# MB9AF1AxM register map
File version: 1.1
CPU: 
Registers are 8-bit, read-write, reset 0x0 unless marked. A register's access mark holds for its fields unless they carry their own. Offsets are from the block's base; [hi:lo] are bit positions; {n}, {i} and the like mark numbered series.

## MFT_PPG — PPG Configuration
Base 0x40024000
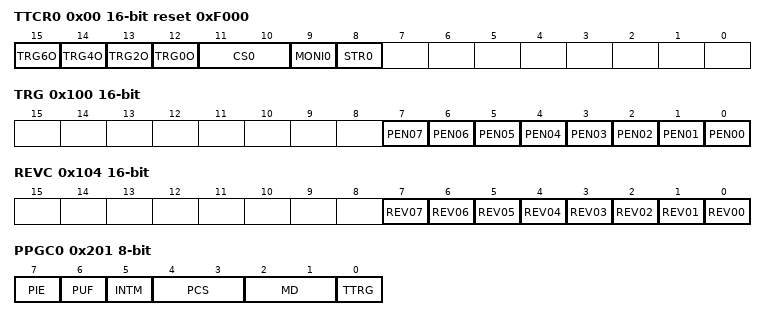
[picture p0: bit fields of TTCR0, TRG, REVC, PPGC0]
0x00 TTCR0 16-bit reset 0xF000 — PPG Start Trigger Control Register 0
  [15] TRG6O — PPG6 trigger stop bit
  [14] TRG4O — PPG4 trigger stop bit
  [13] TRG2O — PPG2 trigger stop bit
  [12] TRG0O — PPG0 trigger stop bit
  [11:10] CS0 — 8-bit UP counter clock select bits for comparison
  [9] MONI0 ro — 8-bit UP counter operation state monitor bit for comparison
  [8] STR0 — 8-bit UP counter operation enable bit for comparison
0x08 COMP0 16-bit (reset mask 0xFF00) — PPG Compare Register 0
0x0C COMP2 — PPG Compare Register 2
0x10 COMP4 32-bit reset not defined — PPG Compare Register 4
0x14 COMP6 32-bit reset not defined — PPG Compare Register 6
0x100 TRG 16-bit — PPG Start Register 0
  [n] PEN{n:02} (n=0..7) — PPG{n} Start Trigger bit
0x104 REVC 16-bit — Output Reverse Register 0
  [n] REV{n:02} (n=0..7) — PPG{n} Output Reverse Enable bit
0x200 PPGC1 32-bit reset not defined — PPG Operation Mode Control Register 1
0x201 PPGC0 — PPG Operation Mode Control Register 0
  [7] PIE — PPG Interrupt Enable bit
  [6] PUF — PPG Counter Underflow bit
  [5] INTM — Interrupt Mode Select bit
  [4:3] PCS — PPG DOWN Counter Operation Clock Select bits
  [2:1] MD — PPG Operation Mode Set bits
  [0] TTRG — PPG start trigger select bit
0x204 PPGC3 32-bit reset not defined — PPG Operation Mode Control Register 3
0x205 PPGC2 32-bit reset not defined — PPG Operation Mode Control Register 2
0x208 PRLL0 reset not defined — PPG0 Reload Registers Low
  [7:0] PRLL — Reload Registers Low
0x209 PRLH0 reset not defined — PPG0 Reload Registers High
  [7:0] PRLH — Reload Registers High
{0x208+4i} PRLL{i} 32-bit reset not defined (i=1..3) — PPG{i} Reload Registers Low
{0x209+4i} PRLH{i} 32-bit reset not defined (i=1..3) — PPG{i} Reload Registers High
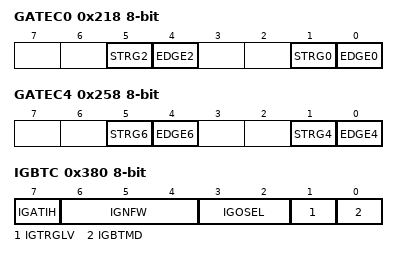
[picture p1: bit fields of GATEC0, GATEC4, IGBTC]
0x218 GATEC0 — PPG Gate Function Control Registers 0
  [5] STRG2 — Select a trigger for PPG2
  [4] EDGE2 — Select Start Effective Level for PPG2
  [1] STRG0 — Select a trigger for PPG0
  [0] EDGE0 — Select Start Effective Level for PPG0
0x240 PPGC5 32-bit reset not defined — PPG Operation Mode Control Register 5
0x241 PPGC4 32-bit reset not defined — PPG Operation Mode Control Register 4
0x244 PPGC7 32-bit reset not defined — PPG Operation Mode Control Register 7
0x245 PPGC6 32-bit reset not defined — PPG Operation Mode Control Register 6
{0x238+4i} PRLL{i} 32-bit reset not defined (i=4..7) — PPG{i} Reload Registers Low
{0x239+4i} PRLH{i} 32-bit reset not defined (i=4..7) — PPG{i} Reload Registers High
0x258 GATEC4 — PPG Gate Function Control Registers 4
  [5] STRG6 — Select a trigger for PPG6
  [4] EDGE6 — Select Start Effective Level for PPG6
  [1] STRG4 — Select a trigger for PPG4
  [0] EDGE4 — Select Start Effective Level for PPG4
0x380 IGBTC — IGBT Mode Control Register
  [7] IGATIH — Stop prohibition mode selection in output active bit
  [6:4] IGNFW — Noise filter width selection bit
  [3:2] IGOSEL — Output level selection bit
  [1] IGTRGLV — Trigger input level selection bit
  [0] IGBTMD — IGBT mode selection bit

## DAC — D/A Converter
Base 0x40028000
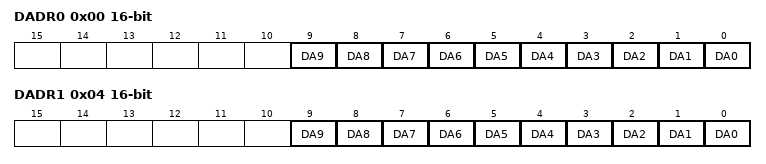
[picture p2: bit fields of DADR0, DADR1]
0x00 DADR0 16-bit reset not defined — D/A Data Register
  [n] DA{n} (n=0..9) — Bit{n} of DADR0
0x02 DACR0 reset not defined — D/A Control Register
  [0] DAE — D/A converter operation enable bit
0x04 DADR1 16-bit reset not defined — D/A Data Register
  [n] DA{n} (n=0..9) — Bit{n} of DADR1
0x06 DACR1 reset not defined — D/A Control Register
  [0] DAE — D/A converter operation enable bit

## EXTI — External Interrupt and NMI Control
Base 0x40030000
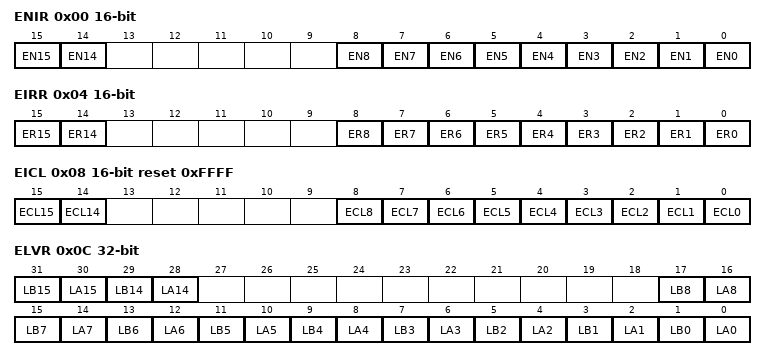
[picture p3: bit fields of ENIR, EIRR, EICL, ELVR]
0x00 ENIR 16-bit — Enable Interrupt Request Register
  [15] EN15 — Bit15 of ENIR
  [14] EN14 — Bit14 of ENIR
  [n] EN{n} (n=0..8) — Bit{n} of ENIR
0x04 EIRR 16-bit ro reset not defined — External Interrupt Request Register
  [15] ER15 — Bit15 of EIRR
  [14] ER14 — Bit14 of EIRR
  [n] ER{n} (n=0..8) — Bit{n} of EIRR
0x08 EICL 16-bit reset 0xFFFF — External Interrupt Clear Register
  [15] ECL15 — Bit15 of EICL
  [14] ECL14 — Bit14 of EICL
  [n] ECL{n} (n=0..8) — Bit{n} of EICL
0x0C ELVR 32-bit — External Interrupt Level Register
  [31] LB15 — Bit31 of ELVR
  [30] LA15 — Bit30 of ELVR
  [29] LB14 — Bit29 of ELVR
  [28] LA14 — Bit28 of ELVR
  [2n+1] LB{n} (n=0..8) — Bit{2n+1} of ELVR
  [2n] LA{n} (n=0..8) — Bit{2n} of ELVR
0x14 NMIRR ro — Non Maskable Interrupt Request Register
  [0] NR — NMI interrupt request detection bit
0x18 NMICL reset 0x1 — Non Maskable Interrupt Clear Register
  [0] NCL — NMI interrupt cause clear bit
